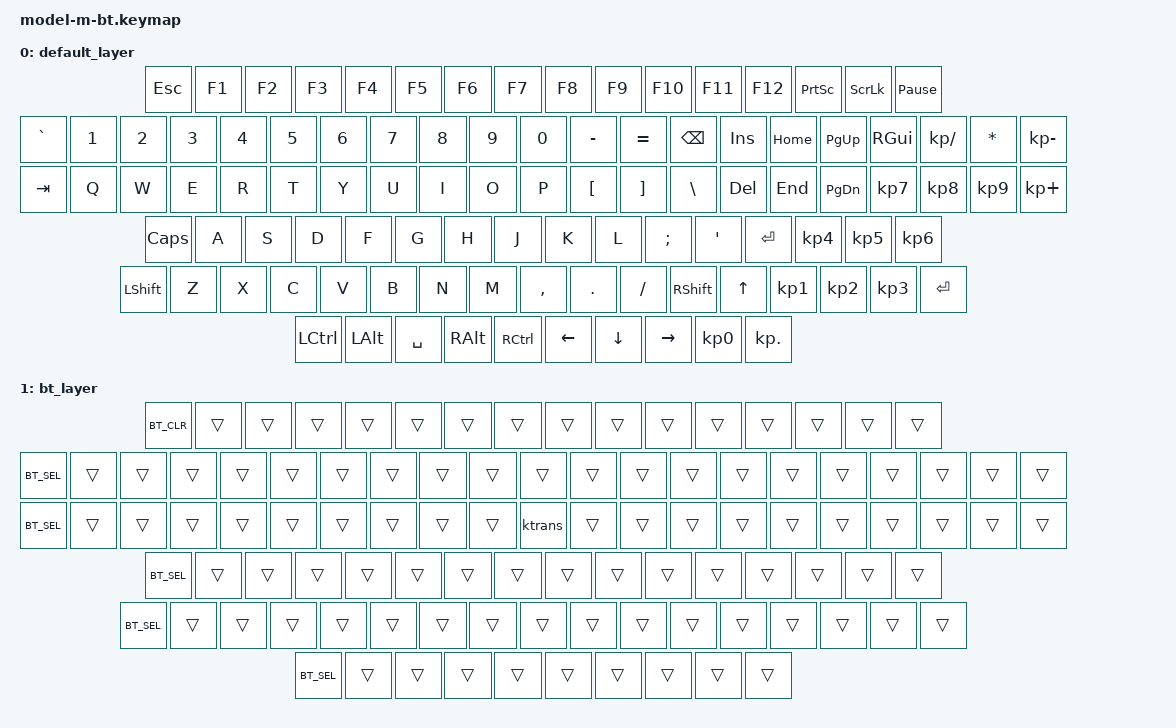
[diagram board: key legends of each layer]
#include <behaviors.dtsi>
#include <dt-bindings/zmk/keys.h>
#include <dt-bindings/zmk/bt.h>
#include <dt-bindings/zmk/matrix_transform.h>

// numpad.overlay
/ {
    chosen {
        zmk,kscan = &kscan0;
        zmk,matrix-transform = &default_transform;
    };

    /* define kscan node with label `kscan0`... */

    default_transform: keymap_transform_0 {
        compatible = "zmk,matrix-transform";
        columns = <16>;
        rows = <8>;

// | MX1  | MX2  | MX3  | MX4  | MX5  | MX6  | MX7  | MX8  | MX9  | MX10 | MX11 | MX12 | MX13 |    MX14     |
// |   MX15   | MX16 | MX17 | MX18 | MX19 | MX20 | MX21 | MX22 | MX23 | MX34 | MX25 | MX26 | MX27 |  MX28   |
// |    MX29    | MX30 | MX31 | MX32 | MX33 | MX34 | MX35 | MX36 | MX37 | MX38 | MX39 | MX40 |     MX41     |
// |     MX42      | MX43 | MX44 | MX45 | MX46 | MX47 | MX48 | MX49 | MX50 | MX51 | MX52 |       MX53       |
// |  MX54  |  MX55  |  MX56  |                  MX57                   |  MX58  |  MX59  |  MX60  |  MX61  |

// ------------------------------------------------------------------------------------------
// | ESC |  F1  |  F2  |  F3  |  F4  |  F5  |  F6  |  F7  |  F8  |  F9  |  F10  | F11 | F12 | PRT SCR | SLCK | PAUSE_BREAK |
// |  `  |  1  |  2  |  3  |  4  |  5  |  6  |  7  |  8  |  9  |  0  |  -  |  =  |   BKSP   | INSERT  |  HOME  |  PAGE_UP  |   WIN  | KP_SLASH | STAR | KP_MINUS |
// | TAB  |  Q  |  W  |  E  |  R  |  T  |  Y  |  U  |  I  |  O  |  P  |  [  |  ]  |   "|"   |  DELETE  |  END |  PAGE_DOWN |  KP_N7 |   KP_N8 | KP_N9 | KP_PLUS  |
// | CAPS  |  A  |  S  |  D  |  F  |  G  |  H  |  J  |  K  |  L  |  ;  |  '  |     ENTER    |                                 KP_N4 |   KP_N5 | KP_N6 |
// |  SHIFT  |  Z  |  X  |  C  |  V  |  B  |  N  |  M  |  ,  |  .  |  /  |      SHIFT       |              UP              |  KP_N1 |   KP_N2 | KP_N3 |    RET   |
// |  CTL      |  ALT  |            SPACE                                  |  ALT   |  CTL  |   LEFT  |  DOWN  |   RIGHT   |  KP_N0 |  KP_DOT |
// ------------------------------------------------------------------------------------------
        map = <
RC(0,2)            RC(2,3) RC(2,4) RC(1,4) RC(0,4) RC(0,6) RC(0,8) RC(1,9) RC(2,9) RC(2,6) RC(3,6) RC(3,11) RC(3,12)                     RC(3,15) RC(4,15) RC(6,14)
RC(2,2)  RC(3,2) RC(3,3) RC(3,4) RC(3,5) RC(2,5) RC(2,7) RC(3,7) RC(3,8) RC(3,9) RC(3,10) RC(2,10) RC(2,8) RC(1,6)                       RC(2,12) RC(2,14) RC(2,13)    RC(6,11) RC(6,12) RC(6,13) RC(7,13) 
RC(1,2)    RC(4,2) RC(4,3) RC(4,4) RC(4,5) RC(1,5) RC(1,7) RC(4,7) RC(4,8) RC(4,9) RC(4,10) RC(1,10) RC(1,8) RC(5,6)                     RC(2,11) RC(3,14) RC(3,13)    RC(4,11) RC(4,12) RC(4,13) RC(4,14) 
RC(1,3)     RC(5,2) RC(5,3) RC(5,4) RC(5,5) RC(0,5) RC(0,7) RC(5,7) RC(5,8) RC(5,9) RC(5,10) RC(0,10) RC(6,6)                                                          RC(1,11) RC(1,12) RC(1,13) 
RC(1,1)       RC(6,2) RC(6,3) RC(6,4) RC(6,5) RC(7,5) RC(7,7) RC(6,7) RC(6,8) RC(6,9) RC(7,10) RC(6,1)                                                RC(0,5)          RC(5,11) RC(5,12) RC(5,13) RC(5,14) 
RC(2,0)        RC(0,15)                           RC(7,6)                    RC(7,15)          RC(6,0)                                         RC(7,14) RC(7,11) RC(7,12)       RC(0,12) RC(0,13) 
        >;
    };

    /* potentially other overlay nodes... */
};


// numpad.keymap
/ {
    keymap {
        compatible = "zmk,keymap";

        default_layer {
// ------------------------------------------------------------------------------------------
// | ESC |  F1  |  F2  |  F3  |  F4  |  F5  |  F6  |  F7  |  F8  |  F9  |  F10  | F11 | F12 | PRT SCR | SLCK | PAUSE_BREAK |
// |  `  |  1  |  2  |  3  |  4  |  5  |  6  |  7  |  8  |  9  |  0  |  -  |  =  |   BKSP   | INSERT  |  HOME  |  PAGE_UP  |   WIN  | KP_SLASH | STAR | KP_MINUS |
// | TAB  |  Q  |  W  |  E  |  R  |  T  |  Y  |  U  |  I  |  O  |  P  |  [  |  ]  |   "|"   |  DELETE  |  END |  PAGE_DOWN |  KP_N7 |   KP_N8 | KP_N9 | KP_PLUS  |
// | CAPS  |  A  |  S  |  D  |  F  |  G  |  H  |  J  |  K  |  L  |  ;  |  '  |     ENTER    |                                 KP_N4 |   KP_N5 | KP_N6 |
// |  SHIFT  |  Z  |  X  |  C  |  V  |  B  |  N  |  M  |  ,  |  .  |  /  |      SHIFT       |              UP              |  KP_N1 |   KP_N2 | KP_N3 |    RET   |
// |  CTL      |  ALT  |            SPACE                                  |  ALT   |  CTL  |   LEFT  |  DOWN  |   RIGHT   |  KP_N0 |  KP_DOT |
// ------------------------------------------------------------------------------------------
            bindings = <
    &kp ESC   &kp F1   &kp F2   &kp F3   &kp F4    &kp F5   &kp F6   &kp F7   &kp F8  &kp F9  &kp F10  &kp F11  &kp F12  &kp PSCRN   &kp SLCK   &kp PAUSE_BREAK
    &kp GRAVE  &kp N1   &kp N2   &kp N3 &kp N4 &kp N5 &kp N6 &kp N7 &kp N8 &kp N9 &kp N0 &kp MINUS &kp EQUAL  &kp BSPC   &kp INS     &kp HOME   &kp PAGE_UP    &kp RGUI   &kp KP_SLASH   &kp STAR   &kp KP_MINUS
    &kp TAB   &kp Q    &kp W    &kp E  &kp R  &kp T  &kp Y  &kp U  &kp I  &kp O  &kp P  &kp LBKT  &kp RBKT  &kp BSLH     &kp DELETE  &kp END    &kp PAGE_DOWN  &kp KP_N7   &kp KP_N8    &kp KP_N9   &kp KP_PLUS
    &kp CLCK  &kp A    &kp S    &kp D  &kp F  &kp G  &kp H  &kp J  &kp K  &kp L  &kp SEMI &kp SQT            &kp RET                                           &kp KP_N4   &kp KP_N5    &kp KP_N6
    &kp LSHFT &kp Z    &kp X    &kp C  &kp V  &kp B  &kp N  &kp M  &kp COMMA &kp DOT &kp FSLH            &kp RSHFT                   &kp UP                    &kp KP_N1   &kp KP_N2    &kp KP_N3   &kp RET
    &kp LCTRL &kp LALT             &kp SPACE                     &kp RALT    &kp RCTRL                                   &kp LEFT    &kp DOWN   &kp RIGHT      &kp KP_N0                &kp KP_DOT  
            >;
        };
        bt_layer {
// ------------------------------------------------------------------------------------------
// |BT CLR|  F1  |  F2  |  F3  |  F4  |  F5  |  F6  |  F7  |  F8  |  F9  |  F10  | F11 | F12 | PRT SCR | SLCK | PAUSE_BREAK |
// |BT 1 |  1  |  2  |  3  |  4  |  5  |  6  |  7  |  8  |  9  |  0  |  -  |  =  |   BKSP   | INSERT  |  HOME  |  PAGE_UP  |   WIN  | KP_SLASH | STAR | KP_MINUS |
// | BT 2 |  Q  |  W  |  E  |  R  |  T  |  Y  |  U  |  I  |  O  |  P  |  [  |  ]  |   "|"   |  DELETE  |  END |  PAGE_DOWN |  KP_N7 |   KP_N8 | KP_N9 | KP_PLUS  |
// | BT 3  |  A  |  S  |  D  |  F  |  G  |  H  |  J  |  K  |  L  |  ;  |  '  |     ENTER    |                                 KP_N4 |   KP_N5 | KP_N6 |
// |  BT 4   |  Z  |  X  |  C  |  V  |  B  |  N  |  M  |  ,  |  .  |  /  |      SHIFT       |              UP              |  KP_N1 |   KP_N2 | KP_N3 |    RET   |
// |  BT 5     |  ALT  |            SPACE                                  |  ALT   |  CTL  |   LEFT  |  DOWN  |   RIGHT   |  KP_N0 |  KP_DOT |
// ------------------------------------------------------------------------------------------
            bindings = <
    &kp BT_CLR   &trans   &trans   &trans   &trans    &trans   &trans   &trans   &trans  &trans  &trans  &trans  &trans  &trans   &trans   &trans
    &kp BT_SEL 0  &trans   &trans   &trans &trans &trans &trans &trans &trans &trans &trans &trans &trans  &trans   &trans     &trans   &trans    &trans   &trans   &trans   &trans
    &kp BT_SEL 1  &trans    &trans    &trans  &trans  &trans  &trans  &trans  &trans  &trans  &ktrans  &trans  &trans  &trans     &trans  &trans    &trans  &trans   &trans    &trans   &trans
    &kp BT_SEL 2  &trans    &trans    &trans  &trans  &trans  &trans  &trans  &trans  &trans  &trans &trans            &trans                                           &trans   &trans    &trans
    &kp BT_SEL 3  &trans    &trans    &trans  &trans  &trans  &trans  &trans  &trans &trans &trans            &trans                   &trans                    &trans   &trans    &trans   &trans
    &kp BT_SEL 4  &trans             &trans                     &trans    &trans                                   &trans    &trans   &trans      &trans                &trans  
            >;
        };
    };
};
